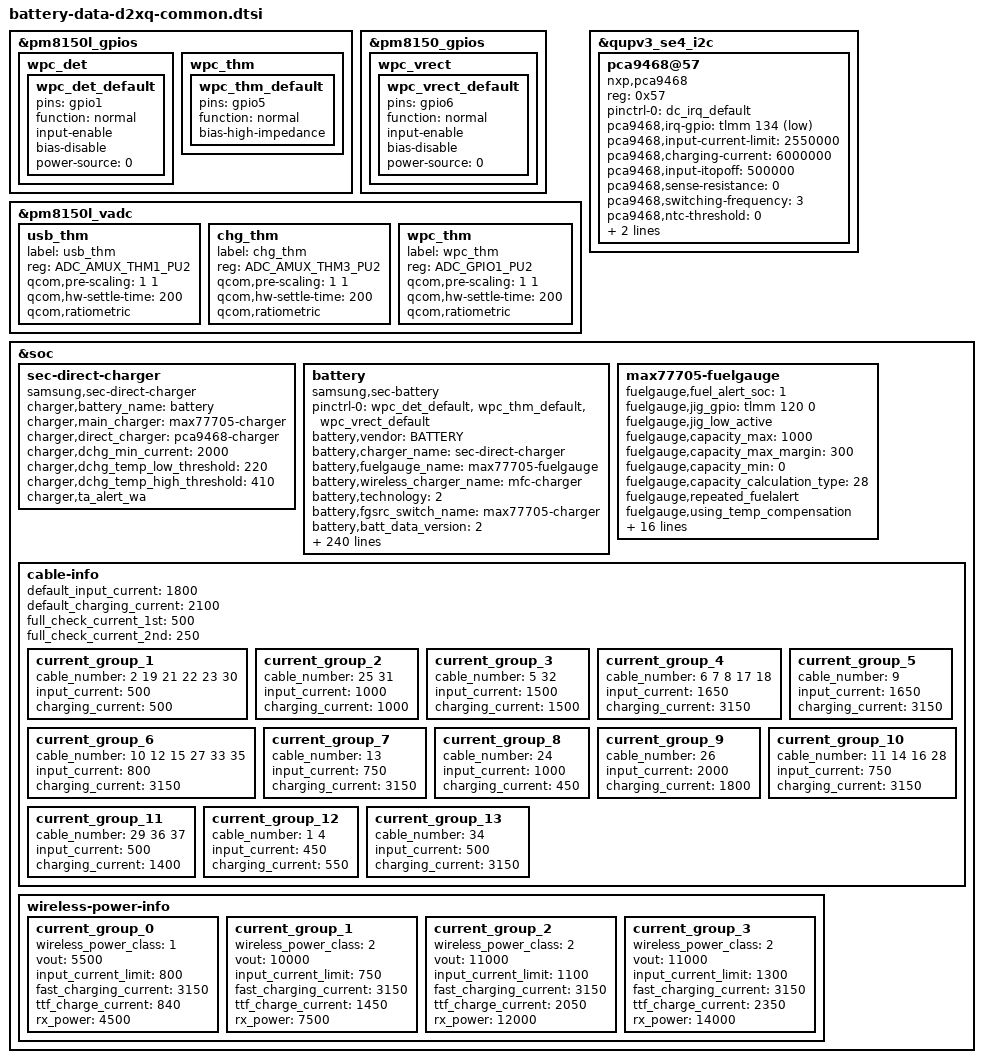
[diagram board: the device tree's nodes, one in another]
/* Copyright (c) 2014, The Linux Foundation. All rights reserved.
 *
 * This program is free software; you can redistribute it and/or modify
 * it under the terms of the GNU General Public License version 2 and
 * only version 2 as published by the Free Software Foundation.
 *
 * This program is distributed in the hope that it will be useful,
 * but WITHOUT ANY WARRANTY; without even the implied warranty of
 * MERCHANTABILITY or FITNESS FOR A PARTICULAR PURPOSE.  See the
 * GNU General Public License for more details.
 */

&pm8150l_gpios {
	wpc_det { /* WPC_DET */
		wpc_det_default: wpc_det_default {
			pins = "gpio1";
			function = "normal";
			input-enable;
			bias-disable;
			power-source = <0>;
		};
	};
	wpc_thm { /* GPIO_05 */
		wpc_thm_default: wpc_thm_default {
			pins = "gpio5";
			function = "normal";
			bias-high-impedance;
		};
	};
};

&pm8150_gpios {
    wpc_vrect { /* VRECT_INT */
        wpc_vrect_default: wpc_vrect_default {
            pins = "gpio6";
            function = "normal";
            input-enable;
            bias-disable;
            power-source = <0>;
        };
    };
};

&pm8150l_vadc {
	usb_thm { /* AMUX_1 */
		label = "usb_thm";
		reg = <ADC_AMUX_THM1_PU2>;
		qcom,pre-scaling = <1 1>;
		qcom,hw-settle-time = <200>;
		qcom,ratiometric;
	};
	chg_thm { /* AMUX_3 */
		label = "chg_thm";
		reg = <ADC_AMUX_THM3_PU2>;
		qcom,pre-scaling = <1 1>;
		qcom,hw-settle-time = <200>;
		qcom,ratiometric;
	};
	wpc_thm { /* GPIO_05 */
		label = "wpc_thm";
		reg = <ADC_GPIO1_PU2>;
		qcom,pre-scaling = <1 1>;
		qcom,hw-settle-time = <200>;
		qcom,ratiometric;
	};
};

&qupv3_se4_i2c {
	status = "okay";

	pca9468@57 {
		compatible = "nxp,pca9468";
		reg = <0x57>;
		pinctrl-names = "default";
		pinctrl-0 = <&dc_irq_default>;

		pca9468,irq-gpio = <&tlmm 134 GPIO_ACTIVE_LOW>; /* DC_IRQ */
		pca9468,input-current-limit = <2550000>; /* 2.55A */
		pca9468,charging-current = <6000000>; /* 6A */
		pca9468,input-itopoff = <500000>; /* 500mA */
		pca9468,sense-resistance = <0>; /* 5mOhm */
		pca9468,switching-frequency = <3>; /* 980KHz */
		pca9468,ntc-threshold = <0>; /* disable */
		pca9468,chg_gpio_en = <&expander_gpios 2 0>; /* DC_CPEN */
		pca9468,ta-mode = <1>; /* 2:1 charging mode */
	};
};

&soc {
	sec-direct-charger {
		status = "okay";
		compatible = "samsung,sec-direct-charger";

		charger,battery_name = "battery";
		charger,main_charger = "max77705-charger";
		charger,direct_charger = "pca9468-charger";

		charger,dchg_min_current = <2000>;
		charger,dchg_temp_low_threshold = <220>;
		charger,dchg_temp_high_threshold = <410>;

		charger,ta_alert_wa;
	};

	battery {
		status = "okay";
		compatible = "samsung,sec-battery";
		pinctrl-names = "default";
		pinctrl-0 = <&wpc_det_default &wpc_thm_default &wpc_vrect_default>;
		battery,vendor = "BATTERY";
		battery,charger_name = "sec-direct-charger";
		battery,fuelgauge_name = "max77705-fuelgauge";
		battery,wireless_charger_name = "mfc-charger";
		battery,technology = <2>; /* POWER_SUPPLY_TECHNOLOGY_LION */
		battery,fgsrc_switch_name = "max77705-charger"; /* Fuelgauge voltage source */

		battery,batt_data_version = <2>;

		battery,chip_vendor = "QCOM";
		battery,temp_adc_type = <1>; /* SEC_BATTERY_ADC_TYPE_AP */

		battery,temp_check_type = <1>; /* SEC_BATTERY_TEMP_CHECK_ADC */
		battery,usb_temp_check_type = <1>;
		battery,chg_temp_check_type = <1>;
		battery,wpc_temp_check_type = <1>;
		battery,dchg_temp_check_type = <1>;

		battery,thermal_source = <2>; /* SEC_BATTERY_THERMAL_SOURCE_ADC */
		battery,usb_thermal_source = <2>; /* SEC_BATTERY_THERMAL_SOURCE_ADC */
		battery,chg_thermal_source = <2>; /* SEC_BATTERY_THERMAL_SOURCE_ADC */
		battery,wpc_thermal_source = <2>; /* SEC_BATTERY_THERMAL_SOURCE_ADC */
		battery,dchg_thermal_source = <3>; /* SEC_BATTERY_THERMAL_SOURCE_CHG_ADC */

		battery,polling_time = <10 30 30 30 3600>;

		battery,temp_table_adc = <146215 170177 195804 226448 264576
						307893 360726 417970 470000 556790
						641738 732309 830081 933822 1041998
						1140527 1246431 1346928 1441565 1525713
						1597512 1660185 1711959>;
		battery,temp_table_data = <900 850 800 750 700
						650 600 550 500 450
						400 350 300 250 200
						150 100 50 0 (-50)
						(-100) (-150) (-200)>;

		battery,usb_temp_table_adc = <246063 286872 331033 382698 442538
						509299 586418 665051 750583 844744
						938948 1035077 1132655 1228157 1320630
						1406076 1484299 1551340 1611310 1659817
						1699826 1733714 1759839>;
		battery,usb_temp_table_data = <900 850 800 750 700
						650 600 550 500 450
						400 350 300 250 200
						150 100 50 0 (-50)
						(-100) (-150) (-200)>;

		battery,chg_temp_table_adc = <119809 144700 169788 200107 237802
						279952 332763 389640 459839 522729
						611656 703697 802659 905968 1014294
						1106768 1213213 1312650 1407979 1497101
						1572901 1635380 1695285>;
		battery,chg_temp_table_data = <900 850 800 750 700
						650 600 550 500 450
						400 350 300 250 200
						150 100 50 0 (-50)
						(-100) (-150) (-200)>;

		battery,wpc_temp_table_adc = <146215 170177 195804 226448 264576
						307893 360726 417970 486050 556790
						641738 732309 830081 933822 1041998
						1140527 1246431 1346928 1441565 1525713
						1597512 1660185 1711959>;
		battery,wpc_temp_table_data = <900 850 800 750 700
						650 600 550 500 450
						400 350 300 250 200
						150 100 50 0 (-50)
						(-100) (-150) (-200)>;

		battery,dchg_temp_table_adc = <110262 133722 157182 187680 225216
						265098 316710 373014 441048 502044
						591192 680340 776526 877404 985320
						1076814 1177692 1278570 1372410 1459212
						1531938 1595280 1649238>;
		battery,dchg_temp_table_data = <900 850 800 750 700
						650 600 550 500 450
						400 350 300 250 200
						150 100 50 0 (-50)
						(-100) (-150) (-200)>;

		battery,wireless_cc_cv = <85>;
		battery,wpc_det = <&pm8150l_gpios 1 GPIO_ACTIVE_HIGH>; /* WPC_DET */
		battery,wpc_en = <&expander_gpios 3 0>; /* WPC_EN */
		battery,mst_pwr_en = <&expander_gpios 21 0>; /* MST_PWR_EN */
		battery,adc_check_count = <5>;

		battery,cable_check_type = <4>; /* SEC_BATTERY_CABLE_CHECK_PSY */
		battery,cable_source_type = <1>; /* SEC_BATTERY_CABLE_SOURCE_EXTERNAL */
		battery,polling_type = <1>; /* SEC_BATTERY_MONITOR_ALARM */
		battery,monitor_initial_count = <0>;

		battery,battery_check_type = <0>; /* SEC_BATTERY_CHECK_NONE */
		battery,check_count = <0>;
		battery,check_adc_max = <1440>;
		battery,check_adc_min = <0>;

		battery,ovp_uvlo_check_type = <3>; /* SEC_BATTERY_OVP_UVLO_CHGPOLLING */

		battery,temp_check_count = <1>;
		battery,temp_highlimit_threshold_event = <700>;
		battery,temp_highlimit_recovery_event = <680>;
		battery,temp_high_threshold_event = <500>;
		battery,temp_high_recovery_event = <480>;
		battery,temp_low_threshold_event = <0>;
		battery,temp_low_recovery_event = <20>;
		battery,temp_highlimit_threshold_normal = <700>;
		battery,temp_highlimit_recovery_normal = <680>;
		battery,temp_high_threshold_normal = <500>;
		battery,temp_high_recovery_normal = <480>;
		battery,temp_low_threshold_normal = <0>;
		battery,temp_low_recovery_normal = <20>;
		battery,temp_highlimit_threshold_lpm = <700>;
		battery,temp_highlimit_recovery_lpm = <680>;
		battery,temp_high_threshold_lpm = <500>;
		battery,temp_high_recovery_lpm = <480>;
		battery,temp_low_threshold_lpm = <0>;
		battery,temp_low_recovery_lpm = <20>;
		battery,wpc_high_threshold_normal = <450>;
		battery,wpc_high_recovery_normal = <430>;
		battery,wpc_low_threshold_normal = <0>;
		battery,wpc_low_recovery_normal = <20>;
		battery,tx_high_threshold = <450>;
		battery,tx_high_recovery = <400>;
		battery,tx_low_threshold = <0>;
		battery,tx_low_recovery = <50>;
		battery,full_check_type = <7>; /* SEC_BATTERY_FULLCHARGED_CHGPSY */
		battery,full_check_type_2nd = <7>; /* SEC_BATTERY_FULLCHARGED_CHGPSY */
		battery,full_check_count = <1>;
		battery,chg_gpio_full_check = <0>;
		battery,chg_polarity_full_check = <1>;

		battery,chg_high_temp = <460>;
		battery,chg_high_temp_recovery = <440>;
		battery,dchg_high_temp = <540>;
		battery,dchg_high_temp_recovery = <400>;
		battery,dchg_high_batt_temp = <400>;
		battery,dchg_high_batt_temp_recovery = <380>;
		battery,chg_input_limit_current = <1000>;
		battery,chg_charging_limit_current = <1900>;
		battery,dchg_input_limit_current = <1000>;
		battery,dchg_charging_limit_current = <2000>;

		battery,charging_limit_by_tx_check = <1>;
		battery,charging_limit_current_by_tx = <1200>;

		battery,wpc_temp_control_source = <1>; /* TEMP_CONTROL_SOURCE_BAT_THM = WPC_THM */
		battery,wpc_high_temp = <410>;
		battery,wpc_high_temp_recovery = <390>;
		battery,wpc_input_limit_current = <600>;
		battery,wpc_charging_limit_current = <1000>;
		battery,wpc_temp_lcd_on_control_source = <1>; /* TEMP_CONTROL_SOURCE_BAT_THM = WPC_THM */
		battery,wpc_lcd_on_high_temp = <410>;
		battery,wpc_lcd_on_high_temp_rec = <390>;
		battery,wpc_lcd_on_input_limit_current = <450>;

		battery,wpc_store_high_temp = <360>;
		battery,wpc_store_high_temp_recovery = <340>;
		battery,wpc_store_charging_limit_current = <400>;
		battery,wpc_store_lcd_on_high_temp = <360>;
		battery,wpc_store_lcd_on_high_temp_rec = <300>;
		battery,wpc_store_lcd_on_charging_limit_current = <400>;

		battery,ta_alert_wa;

		battery,sleep_mode_limit_current = <800>;
		battery,wc_full_input_limit_current = <100>;

		battery,mix_high_temp = <420>;
		battery,mix_high_chg_temp = <500>;
		battery,mix_high_temp_recovery = <390>;

		/* SEC_BATTERY_FULL_CONDITION_NOTIMEFULL | SEC_BATTERY_FULL_CONDITION_VCELL */
		battery,full_condition_type = <9>;
		battery,full_condition_soc = <93>;
		battery,full_condition_vcell = <4250>;

		battery,recharge_check_count = <1>;
		battery,recharge_condition_type = <4>; /* SEC_BATTERY_RECHARGE_CONDITION_VCELL */
		battery,recharge_condition_soc = <98>;
		battery,recharge_condition_vcell = <4280>;

		battery,charging_total_time = <14400>;
		battery,hv_charging_total_time = <10800>;
		battery,normal_charging_total_time = <18000>;
		battery,usb_charging_total_time = <36000>;
		battery,recharging_total_time = <5400>;
		battery,charging_reset_time = <0>;

		battery,chg_float_voltage = <4350>;
		battery,chg_ocp_current = <6200>;
		battery,chg_ocp_dtc = <100>;

		battery,pre_afc_work_delay = <2000>;
		battery,pre_wc_afc_work_delay = <4000>;
		battery,pre_afc_input_current = <500>;
		battery,pre_wc_afc_input_current = <500>;
		battery,prepare_ta_delay = <0>; /* msec */

		battery,swelling_high_temp_block = <410>;
		battery,swelling_high_temp_recov = <390>;
		battery,swelling_wc_high_temp_block = <420>;
		battery,swelling_wc_high_temp_recov = <410>;
		battery,swelling_low_temp_block_1st = <150>;
		battery,swelling_low_temp_recov_1st = <170>;
		battery,swelling_low_temp_block_2nd = <50>;
		battery,swelling_low_temp_recov_2nd = <70>;
		battery,swelling_low_temp_3rd_ctrl;
		battery,swelling_low_temp_block_3rd = <180>;
		battery,swelling_low_temp_recov_3rd = <190>;
		battery,swelling_low_temp_4th_ctrl;
		battery,swelling_low_temp_block_4th = <220>;
		battery,swelling_low_temp_recov_4th = <230>;
		battery,swelling_low_temp_5th_ctrl;
		battery,swelling_low_temp_block_5th = <250>;
		battery,swelling_low_temp_recov_5th = <260>;

		battery,swelling_low_temp_current = <1000>;	/* 0.24C */
		battery,swelling_low_temp_current_2nd = <400>;	/* 0.1C */
		battery,swelling_low_temp_current_3rd = <2000>;	/* 0.48C */
		battery,swelling_low_temp_current_4th = <3000>;	/* 0.72C */
		battery,swelling_low_temp_current_5th = <4100>;	/* 1.0C */
		battery,swelling_low_temp_topoff = <250>;	/* 0.05C */
		battery,swelling_high_temp_current = <1500>;	/* 0.36C */
		battery,swelling_high_temp_topoff = <250>;	/* 0.05C */
		battery,swelling_wc_high_temp_current = <1000>;	/* 0.24C */
		battery,swelling_wc_low_temp_current = <1000>;	/* 0.24C */
		battery,swelling_wc_low_temp_current_2nd = <400>;	/* 0.1C */
		battery,swelling_wc_low_temp_current_3rd = <2000>;	/* 0.72C */

		battery,swelling_drop_float_voltage = <4150>;
		battery,swelling_high_rechg_voltage = <4000>;
		battery,swelling_low_rechg_thr = <150>;

		battery,siop_input_limit_current = <1200>;
		battery,siop_charging_limit_current = <1000>;
		battery,siop_hv_input_limit_current = <700>;
		battery,siop_hv_input_limit_current_2nd = <450>;
		battery,siop_hv_charging_limit_current = <1000>;
		battery,siop_apdo_input_limit_current = <1200>;
		battery,siop_apdo_charging_limit_current = <2000>;

		battery,siop_wireless_input_limit_current = <600>;
		battery,siop_wireless_charging_limit_current = <850>;
		battery,siop_hv_wireless_input_limit_current = <700>;
		battery,siop_hv_wireless_charging_limit_current = <850>;
		battery,siop_store_hv_wireless_input_limit_current = <450>;

		battery,wireless_otg_input_current = <900>;

		battery,ttf_hv_charge_current = <2850>;
		battery,ttf_hv_wireless_charge_current = <1450>;
		battery,ttf_wireless_charge_current = <840>;
		battery,ttf_dc25_charge_current = <5300>;
		battery,ttf_dc45_charge_current = <6400>;

		battery,rp_current_rp1 = <500>;
		battery,rp_current_rp2 = <1500>;
		battery,rp_current_rp3 = <3000>;
		battery,rp_current_rdu_rp3 = <2100>;
		battery,rp_current_abnormal_rp3 = <1800>;

		battery,pd_charging_charge_power = <15000>;
		battery,max_charging_current = <3150>;
		battery,max_charging_charge_power = <45000>; /* 45W */

		/* cycle, chg_float_voltage, recharge_condition_vcell, full_condition_vcell, full_condition_soc, step charging condition */
		battery,age_data = <0 4350 4280 4250 93 45
				50 4350 4280 4250 93 45
				100 4340 4270 4240 92 45
				150 4340 4270 4240 92 45
				200 4330 4260 4230 92 45
				300 4330 4260 4230 92 45
				400 4310 4240 4210 91 45
				700 4290 4220 4190 90 45
				1000 4240 4170 4140 89 45>;

		battery,health_condition = <
				/* CYCLE ASOC */
				900 75	/* GOOD */
				1200 65 /* NORMAL */
				1500 55 /* AGED */
				>;

		/* step charging option */
		battery,step_charging_type = <0>;

		/* direct step charging option */
		battery,dc_step_chg_type = <0xE9>; /* origin(0x6B), soc option is temporary removed */
		battery,dc_step_chg_charge_power = <22000>;
		battery,dc_step_chg_step = <3>;
		battery,dc_step_chg_step_2nd = <0>;
		battery,dc_step_chg_cond_vol = <4130 4310 4350>; /*<45w 3step> STEP_CHARGING_CONDITION_VOLTAGE */ 
		battery,dc_step_chg_cond_iin = <2700 1900 0>; /* <45w 3step> STEP_CHARGING_CONDITION_INPUT_CURRENT */
		battery,dc_step_chg_iin_check_cnt = <3>;
		battery,dc_step_chg_cond_soc = <30 65 100>; /* <45w 3step> STEP_CHARGING_CONDITION_SOC */
		battery,dc_step_chg_val_vfloat = <4130 4310 4350
						4120 4290 4350
						4110 4270 4340
						4100 4250 4340
						4090 4230 4330
						4080 4230 4330
						4070 4230 4310
						4060 4230 4290
						4050 4230 4240>; /* <45w 3step> STEP_CHARGING_CONDITION_FLOAT_VOLTAGE */
		battery,dc_step_chg_val_iout = <7400 5400 3800
						7200 5300 3700
						7000 5200 3600
						6800 5100 3500
						6800 5000 3400
						6800 4900 3300
						6800 4800 3200
						6700 4700 3100
						6600 4600 3000>; /* <45w 3step> */

		battery,max_input_voltage = <9000>; /* mV */
		battery,max_input_current = <3000>;  /* mA */

		battery,enable_sysovlo_irq;
		battery,enable_noise_wa;
		battery,dis_auto_shipmode_temp_ctrl;

		battery,standard_curr = <3150>;
		battery,expired_time = <10800>;
		battery,recharging_expired_time = <5400>;

		battery,battery_full_capacity = <4300>;
		battery,cisd_max_voltage_thr = <4400>; /* batttery ovp dettection voltage */
		battery,cisd_alg_index = <8>;
		battery,ignore_cisd_index = <0 0>;
		battery,ignore_cisd_index_d = <0 80>; /* Do not use BUCK_OFF_PER_DAY, DROP_SENSOR_PER_DAY */

		battery,tx_stop_capacity = <30>;
		battery,tx_minduty_default = <20>;
		battery,tx_minduty_5V = <50>;

		battery,tx_uno_iout = <1500>;
		battery,tx_mfc_iout_gear = <1500>;
		battery,tx_mfc_iout_phone = <1100>;
		battery,tx_mfc_iout_phone_5v = <300>;
		battery,tx_mfc_iout_lcd_on = <900>;

		battery,support_unknown_wpcthm;

		io-channels = <&pm8150l_vadc ADC_GPIO1_PU2>, <&pm8150l_vadc ADC_AMUX_THM3_PU2>, <&pm8150l_vadc ADC_GPIO1_PU2>, <&pm8150l_vadc ADC_AMUX_THM1_PU2>;
		io-channel-names = "adc-temp", "adc-chg-temp", "adc-wpc-temp", "adc-usb-temp";
	};

	max77705-fuelgauge {
		/* for 4400mAh battery */
		status = "okay";
		fuelgauge,fuel_alert_soc = <1>;
		fuelgauge,jig_gpio = <&tlmm 120 0>; /* IFC_SENSE_INT_AP */
		fuelgauge,jig_low_active;
		fuelgauge,capacity_max = <1000>;
		fuelgauge,capacity_max_margin = <300>;
		fuelgauge,capacity_min = <0>;
		fuelgauge,capacity_calculation_type = <28>;
		fuelgauge,repeated_fuelalert;
		fuelgauge,using_temp_compensation;
		fuelgauge,low_temp_limit = <100>;
		fuelgauge,using_hw_vempty;
		fuelgauge,v_empty = <0xA7E2>; /* Empty: 3350mV, Recover: 3480mV */
		fuelgauge,v_empty_origin = <0x7D54>; /* Empty: 2500mV, Recover: 3360mV */
		fuelgauge,sw_v_empty_voltage = <3200>;
		fuelgauge,sw_v_empty_voltage_cisd = <3100>;
		fuelgauge,sw_v_empty_recover_voltage = <3480>;
		fuelgauge,fg_resistor = <5>;
		fuelgauge,capacity = <0x0686>; /*capacity = fullcapnom = DesignCap*/
		fuelgauge,fg_reset_wa_data = <0x0686 0x3200 0x0191 0x0024 0x1426>; /* fullcapnom(=capacity), dPacc, dQacc,  rcomp0, tempco */
		fuelgauge,discharge_temp_threshold = <600>;
		fuelgauge,discharge_volt_threshold = <4200>;
		fuelgauge,ttf_capacity = <3750>;
		fuelgauge,cv_data = <
			3007	758	2334
			2628	777	2227
			2396	793	2132
			2140	810	2015
			1800	834	1850
			1411	856	1602
			1209	870	1435
			1000	883	1253
			871	894	1062
			734	902	913
			681	907	795
			584	922	650
			531	938	568
			513	942	483
			497	953	384
			428	963	305
			395	974	213
			365	994	92
			316	1000	0
			>;
	};

/* sec_battery_cable
 *   0	UNKNOWN,
 *   1	NONE,
 *   2	PREPARE_TA,
 *   3	TA,
 *   4	USB,
 *   5	USB_CDP,
 *   6	9V_TA,
 *   7	9V_ERR,
 *   8	9V_UNKNOWN,
 *   9	12V_TA,
 *  10	WIRELESS,
 *  11	HV_WIRELESS,
 *  12	PMA_WIRELESS,
 *  13	WIRELESS_PACK,
 *  14	WIRELESS_HV_PACK,
 *  15	WIRELESS_STAND,
 *  16	WIRELESS_HV_STAND,
 *  17	QC20,
 *  18	QC30,
 *  19	PDIC,
 *  20	UARTOFF,
 *  21	OTG,
 *  22	LAN_HUB,
 *  23	POWER_SHARING,
 *  24	HMT_CONNECTED,
 *  25	HMT_CHARGE,
 *  26	HV_TA_CHG_LIMIT,
 *  27	WIRELESS_VEHICLE,
 *  28	WIRELESS_HV_VEHICLE,
 *  29	PREPARE_WIRELESS_HV,
 *  30  TIMEOUT,
 *  31  SMART_OTG,
 *  32  SMART_NOTG,
 *  33  WIRELESS_TX,
 *  34	HV_WIRELESS_20,
 *  35	HV_WIRELESS_20_LIMIT,
 *  36	WIRELESS_FAKE,
 *  37  PREPARE_WIRELESS_20,
 *  38	CABLE_PDIC_APDO,
 *  39	CABLE_MAX,
 */
	cable-info {
		default_input_current = <1800>;
		default_charging_current = <2100>;
		full_check_current_1st = <500>;
		full_check_current_2nd = <250>;

		current_group_1 {
			cable_number = <2 19 21 22 23 30>;
			input_current = <500>;
			charging_current = <500>;
		};
		current_group_2 {
			cable_number = <25 31>;
			input_current = <1000>;
			charging_current = <1000>;
		};
		current_group_3 {
			cable_number = <5 32>;
			input_current = <1500>;
			charging_current = <1500>;
		};
		current_group_4 {
			cable_number = <6 7 8 17 18>;
			input_current = <1650>;
			charging_current = <3150>;
		};
		current_group_5 {
			cable_number = <9>;
			input_current = <1650>;
			charging_current = <3150>;
		};
		current_group_6 {
			cable_number = <10 12 15 27 33 35>;
			input_current = <800>;
			charging_current = <3150>;
		};
		current_group_7 {
			cable_number = <13>;
			input_current = <750>;
			charging_current = <3150>;
		};
		current_group_8 {
			cable_number = <24>;
			input_current = <1000>;
			charging_current = <450>;
		};
		current_group_9 {
			cable_number = <26>;
			input_current = <2000>;
			charging_current = <1800>;
		};
		current_group_10 {
			cable_number = <11 14 16 28>;
			input_current = <750>;
			charging_current = <3150>;
		};
		current_group_11 {
			cable_number = <29 36 37>;
			input_current = <500>;
			charging_current = <1400>;
		};
		current_group_12 {
			cable_number = <1 4>;
			input_current = <450>;
			charging_current = <550>;
		};
		current_group_13 {
			cable_number = <34>;
			input_current = <500>;
			charging_current = <3150>;
		};
	};
	wireless-power-info {
		current_group_0 {
			wireless_power_class = <1>;
			vout = <5500>;
			input_current_limit = <800>;
			fast_charging_current = <3150>;
			ttf_charge_current = <840>;
			rx_power = <4500>;
		};
		current_group_1 {
			wireless_power_class = <2>;
			vout = <10000>;
			input_current_limit = <750>;
			fast_charging_current = <3150>;
			ttf_charge_current = <1450>;
			rx_power = <7500>;
		};
		current_group_2 {
			wireless_power_class = <2>;
			vout = <11000>;
			input_current_limit = <1100>;
			fast_charging_current = <3150>;
			ttf_charge_current = <2050>;
			rx_power = <12000>;
		};
		current_group_3 {
			wireless_power_class = <2>;
			vout = <11000>;
			input_current_limit = <1300>;
			fast_charging_current = <3150>;
			ttf_charge_current = <2350>;
			rx_power = <14000>;
		};
	};
};
